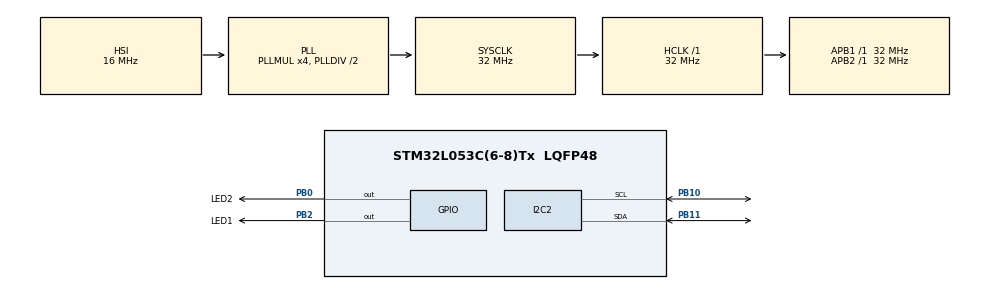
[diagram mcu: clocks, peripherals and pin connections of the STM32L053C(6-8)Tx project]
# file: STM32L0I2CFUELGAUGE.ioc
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I2C2.Timing=0x00707CBB
Mcu.Family=STM32L0
Mcu.Name=STM32L053C(6-8)Tx
Mcu.Package=LQFP48
PA13.Mode=Serial_Wire
PA13.Signal=SYS_SWDIO
PA14.Mode=Serial_Wire
PA14.Signal=SYS_SWCLK
PB0.GPIO_Label=LED2
PB0.Signal=GPIO_Output
PB10.GPIO_PuPdOD=GPIO_NOPULL
PB10.Mode=I2C
PB10.Signal=I2C2_SCL
PB11.GPIO_PuPdOD=GPIO_NOPULL
PB11.Mode=I2C
PB11.Signal=I2C2_SDA
PB2.GPIO_Label=LED1
PB2.Signal=GPIO_Output
ProjectManager.HeapSize=0x200
ProjectManager.StackSize=0x400
ProjectManager.TargetToolchain=SW4STM32
RCC.AHBFreq_Value=32000000
RCC.APB1Freq_Value=32000000
RCC.APB1TimFreq_Value=32000000
RCC.APB2Freq_Value=32000000
RCC.APB2TimFreq_Value=32000000
RCC.HCLKFreq_Value=32000000
RCC.HSE_VALUE=8000000
RCC.HSI16_VALUE=16000000
RCC.HSI48_VALUE=48000000
RCC.HSI_VALUE=16000000
RCC.LSE_VALUE=32768
RCC.MSI_VALUE=2097000
RCC.PLLMUL=RCC_PLLMUL_4
RCC.SYSCLKFreq_VALUE=32000000
RCC.SYSCLKSource=RCC_SYSCLKSOURCE_PLLCLK
RCC.VCOOutputFreq_Value=64000000
board=custom

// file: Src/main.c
/* USER CODE BEGIN Header */
/**
  ******************************************************************************
  * @file           : main.c
  * @brief          : Main program body
  ******************************************************************************
  * @attention
  *
  * <h2><center>&copy; Copyright (c) 2019 STMicroelectronics.
  * All rights reserved.</center></h2>
  *
  * This software component is licensed by ST under BSD 3-Clause license,
  * the "License"; You may not use this file except in compliance with the
  * License. You may obtain a copy of the License at:
  *                        opensource.org/licenses/BSD-3-Clause
  *
  ******************************************************************************
  */
/* USER CODE END Header */

#include "main.h"

I2C_HandleTypeDef hi2c2;

void SystemClock_Config(void);
static void MX_GPIO_Init(void);
static void MX_I2C2_Init(void);

int main(void)
{

  /* MCU Configuration--------------------------------------------------------*/

  /* Reset of all peripherals, Initializes the Flash interface and the Systick. */
  HAL_Init();

  /* Configure the system clock */
  SystemClock_Config();

  /* Initialize all configured peripherals */
  MX_GPIO_Init();
  MX_I2C2_Init();
  /* USER CODE BEGIN 2 */

  FG_I2C_Setup(&hi2c2);
  uint16_t battery_percentage = FG_I2C_Read_SOC(&hi2c2);
  //uint16_t voltage_reading = FG_I2C_Read_Voltage(&hi2c2);

  if (battery_percentage)
  {
      asm("nop");
  }

  /* USER CODE END 2 */

  /* Infinite loop */
  /* USER CODE BEGIN WHILE */
  while (1)
  {
      HAL_GPIO_WritePin(LED1_GPIO_Port, LED1_Pin, GPIO_PIN_SET);
    /* USER CODE END WHILE */

  }
}

void SystemClock_Config(void)
{
  RCC_OscInitTypeDef RCC_OscInitStruct = {0};
  RCC_ClkInitTypeDef RCC_ClkInitStruct = {0};

  /** Configure the main internal regulator output voltage
  */
  __HAL_PWR_VOLTAGESCALING_CONFIG(PWR_REGULATOR_VOLTAGE_SCALE1);
  /** Initializes the CPU, AHB and APB busses clocks
  */
  RCC_OscInitStruct.OscillatorType = RCC_OSCILLATORTYPE_HSI;
  RCC_OscInitStruct.HSIState = RCC_HSI_ON;
  RCC_OscInitStruct.HSICalibrationValue = RCC_HSICALIBRATION_DEFAULT;
  RCC_OscInitStruct.PLL.PLLState = RCC_PLL_ON;
  RCC_OscInitStruct.PLL.PLLSource = RCC_PLLSOURCE_HSI;
  RCC_OscInitStruct.PLL.PLLMUL = RCC_PLLMUL_4;
  RCC_OscInitStruct.PLL.PLLDIV = RCC_PLLDIV_2;
  if (HAL_RCC_OscConfig(&RCC_OscInitStruct) != HAL_OK)
  {
    Error_Handler();
  }
  /** Initializes the CPU, AHB and APB busses clocks
  */
  RCC_ClkInitStruct.ClockType = RCC_CLOCKTYPE_HCLK|RCC_CLOCKTYPE_SYSCLK
                              |RCC_CLOCKTYPE_PCLK1|RCC_CLOCKTYPE_PCLK2;
  RCC_ClkInitStruct.SYSCLKSource = RCC_SYSCLKSOURCE_PLLCLK;
  RCC_ClkInitStruct.AHBCLKDivider = RCC_SYSCLK_DIV1;
  RCC_ClkInitStruct.APB1CLKDivider = RCC_HCLK_DIV1;
  RCC_ClkInitStruct.APB2CLKDivider = RCC_HCLK_DIV1;

  if (HAL_RCC_ClockConfig(&RCC_ClkInitStruct, FLASH_LATENCY_1) != HAL_OK)
  {
    Error_Handler();
  }
}

static void MX_I2C2_Init(void)
{

  hi2c2.Instance = I2C2;
  hi2c2.Init.Timing = 0x00707CBB;
  hi2c2.Init.OwnAddress1 = 0;
  hi2c2.Init.AddressingMode = I2C_ADDRESSINGMODE_7BIT;
  hi2c2.Init.DualAddressMode = I2C_DUALADDRESS_DISABLE;
  hi2c2.Init.OwnAddress2 = 0;
  hi2c2.Init.OwnAddress2Masks = I2C_OA2_NOMASK;
  hi2c2.Init.GeneralCallMode = I2C_GENERALCALL_DISABLE;
  hi2c2.Init.NoStretchMode = I2C_NOSTRETCH_DISABLE;
  if (HAL_I2C_Init(&hi2c2) != HAL_OK)
  {
    Error_Handler();
  }
  /** Configure Analogue filter
  */
  if (HAL_I2CEx_ConfigAnalogFilter(&hi2c2, I2C_ANALOGFILTER_ENABLE) != HAL_OK)
  {
    Error_Handler();
  }
  /** Configure Digital filter
  */
  if (HAL_I2CEx_ConfigDigitalFilter(&hi2c2, 0) != HAL_OK)
  {
    Error_Handler();
  }

}

static void MX_GPIO_Init(void)
{
  GPIO_InitTypeDef GPIO_InitStruct = {0};

  /* GPIO Ports Clock Enable */
  __HAL_RCC_GPIOB_CLK_ENABLE();
  __HAL_RCC_GPIOA_CLK_ENABLE();

  /*Configure GPIO pin Output Level */
  HAL_GPIO_WritePin(GPIOB, LED2_Pin|LED1_Pin, GPIO_PIN_RESET);

  /*Configure GPIO pins : LED2_Pin LED1_Pin */
  GPIO_InitStruct.Pin = LED2_Pin|LED1_Pin;
  GPIO_InitStruct.Mode = GPIO_MODE_OUTPUT_PP;
  GPIO_InitStruct.Pull = GPIO_NOPULL;
  GPIO_InitStruct.Speed = GPIO_SPEED_FREQ_LOW;
  HAL_GPIO_Init(GPIOB, &GPIO_InitStruct);

}

void Error_Handler(void)
{
}

/************************ (C) COPYRIGHT STMicroelectronics *****END OF FILE****/
